# ATmega406 device description
Architecture: AVR8; Family: megaAVR
Registers are 8-bit, access not given, no defined reset value unless marked. A register's access mark holds for its fields unless they carry their own. Offsets are from the block's base; [hi:lo] are bit positions.

## TC0 (TC8 module) — Timer/Counter, 8-bit
Instances: TC0 0x00
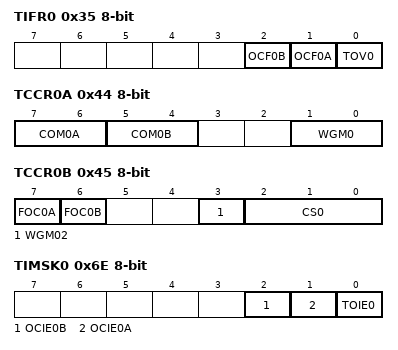
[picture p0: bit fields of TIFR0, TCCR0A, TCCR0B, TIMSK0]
0x35 TIFR0 — Timer/Counter Interrupt Flag register
  [2] OCF0B — Output Compare Flag
  [1] OCF0A — Output Compare Flag
  [0] TOV0 — Overflow Flag
0x44 TCCR0A — Timer/Counter0 Control Register
  [7:6] COM0A — Force Output Compare
  [5:4] COM0B
  [1:0] WGM0 — Clock Select0 bits
0x45 TCCR0B — Timer/Counter0 Control Register
  [7] FOC0A — Force Output Compare
  [6] FOC0B — Waveform Generation Mode
  [3] WGM02
  [2:0] CS0 — Clock Select0 bits
    0=No Clock Source (Stopped); 1=Running, No Prescaling; 2=Running, CLK/8; 3=Running, CLK/64; 4=Running, CLK/256; 5=Running, CLK/1024; 6=Running, ExtClk Tx Falling Edge; 7=Running, ExtClk Tx Rising Edge
0x46 TCNT0 — Timer Counter 0
0x47 OCR0A — Output compare Register A
0x48 OCR0B — Output compare Register B
0x6E TIMSK0 — Timer/Counter Interrupt Mask Register
  [2] OCIE0B — Output Compare Interrupt Enable
  [1] OCIE0A — Output Compare Interrupt Enable
  [0] TOIE0 — Overflow Interrupt Enable

## PORTA — I/O Port
Instances: PORTA 0x00
0x20 PINA — Port A Input Pins
0x21 DDRA — Port A Data Direction Register
0x22 PORTA — Port A Data Register

## PORTB — I/O Port
Instances: PORTB 0x00
0x23 PINB — Port B Input Pins
0x24 DDRB — Port B Data Direction Register
0x25 PORTB — Port B Data Register

## PORTC — I/O Port
Instances: PORTC 0x00
0x28 PORTC bits used 0 — Port C Data Register

## PORTD — I/O Port
Instances: PORTD 0x00
0x29 PIND bits used 1:0 — Input Pins, Port D
0x2A DDRD bits used 1:0 — Data Direction Register, Port D
0x2B PORTD bits used 1:0 — Data Register, Port D

## BOOT_LOAD — Bootloader
Instances: BOOT_LOAD 0x00
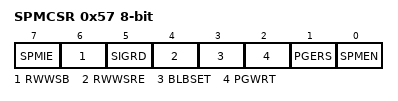
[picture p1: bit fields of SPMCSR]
0x57 SPMCSR — Store Program Memory Control Register
  [7] SPMIE — SPM Interrupt Enable
  [6] RWWSB — Read While Write Section Busy
  [5] SIGRD — Signature Row Read
  [4] RWWSRE — Read While Write section read enable
  [3] BLBSET — Boot Lock Bit Set
  [2] PGWRT — Page Write
  [1] PGERS — Page Erase
  [0] SPMEN — Store Program Memory Enable

## TWI — Two Wire Serial Interface
Instances: TWI 0x00
0xB8 TWBR — TWI Bit Rate register
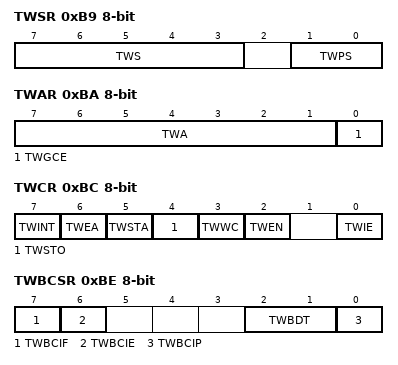
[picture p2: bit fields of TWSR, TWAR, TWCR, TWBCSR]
0xB9 TWSR — TWI Status Register
  [7:3] TWS (bit 3 of the value upward) — TWI Status
  [1:0] TWPS — TWI Prescaler
    0=1; 1=4; 2=16; 3=64
0xBA TWAR — TWI (Slave) Address register
  [7:1] TWA — TWI (Slave) Address register Bits
  [0] TWGCE — TWI General Call Recognition Enable Bit
0xBB TWDR — TWI Data register
0xBC TWCR — TWI Control Register
  [7] TWINT — TWI Interrupt Flag
  [6] TWEA — TWI Enable Acknowledge Bit
  [5] TWSTA — TWI Start Condition Bit
  [4] TWSTO — TWI Stop Condition Bit
  [3] TWWC — TWI Write Collition Flag
  [2] TWEN — TWI Enable Bit
  [0] TWIE — TWI Interrupt Enable
0xBD TWAMR — TWI (Slave) Address Mask Register
  [7:1] TWAM
0xBE TWBCSR — TWI Bus Control and Status Register
  [7] TWBCIF — TWI Bus Connect/Disconnect Interrupt Flag
  [6] TWBCIE — TWI Bus Connect/Disconnect Interrupt Enable
  [2:1] TWBDT — TWI Bus Disconnect Time-out Period
    0=250ms; 1=500ms; 2=1000ms; 3=2000ms
  [0] TWBCIP — TWI Bus Connect/Disconnect Interrupt Polarity

## BANDGAP
Instances: BANDGAP 0x00
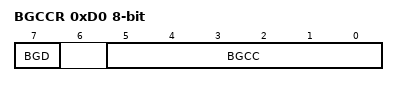
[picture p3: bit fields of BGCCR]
0xD0 BGCCR — Bandgap Calibration Register
  [7] BGD — Setting the BGD bit to one will disable the bandgap voltage reference. This bit must be cleared before enabling CC-ADC or V-ADC, and must remain unset while either ADC is enabled.
  [5:0] BGCC — BG Calibration of PTAT Current Bits
0xD1 BGCRR — Bandgap Calibration of Resistor Ladder

## EEPROM
Instances: EEPROM 0x00
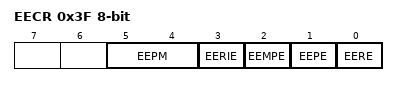
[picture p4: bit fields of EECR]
0x3F EECR — EEPROM Control Register
  [5:4] EEPM — EEPROM Programming Mode Bits
    0=Erase and Write in one operation; 1=Erase Only; 2=Write Only
  [3] EERIE — EEPROM Ready Interrupt Enable
  [2] EEMPE — EEPROM Master Programming Enable
  [1] EEPE — EEPROM Programming Enable
  [0] EERE — EEPROM Read Enable
0x40 EEDR — EEPROM Data Register
0x41 EEAR 16-bit bits used 8:0 — EEPROM Address Register Bytes
